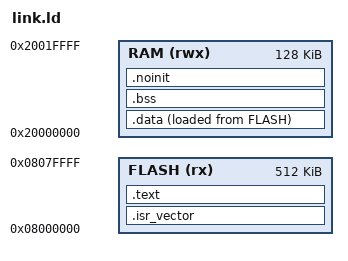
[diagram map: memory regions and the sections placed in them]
/* STM32F446RE: 512 KiB of flash, 128 KiB of contiguous SRAM (SRAM1 + SRAM2). */
MEMORY
{
  FLASH (rx)  : ORIGIN = 0x08000000, LENGTH = 512K
  RAM   (rwx) : ORIGIN = 0x20000000, LENGTH = 128K
}

ENTRY(reset_handler)

_estack = ORIGIN(RAM) + LENGTH(RAM);

SECTIONS
{
  .isr_vector :
  {
    KEEP(*(.isr_vector))
  } > FLASH

  .text :
  {
    *(.text*)
    *(.rodata*)
    . = ALIGN(4);
  } > FLASH

  .data :
  {
    _sdata = .;
    *(.data*)
    . = ALIGN(4);
    _edata = .;
  } > RAM AT > FLASH
  _sidata = LOADADDR(.data);

  .bss (NOLOAD) :
  {
    _sbss = .;
    *(.bss*)
    *(COMMON)
    . = ALIGN(4);
    _ebss = .;
  } > RAM

  /* Survives a reset: the start-up code neither copies nor clears it. */
  .noinit (NOLOAD) :
  {
    *(.noinit*)
  } > RAM

  /DISCARD/ :
  {
    *(.ARM.exidx*)
    *(.ARM.attributes)
    *(.comment)
  }
}
